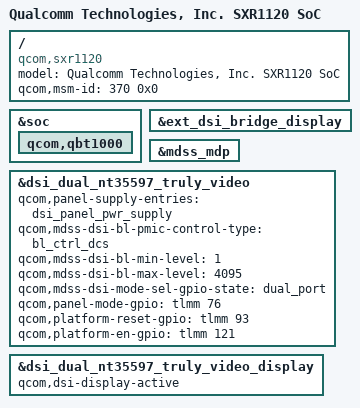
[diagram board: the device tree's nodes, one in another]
/*
 * Copyright (c) 2018, The Linux Foundation. All rights reserved.
 *
 * This program is free software; you can redistribute it and/or modify
 * it under the terms of the GNU General Public License version 2 and
 * only version 2 as published by the Free Software Foundation.
 *
 * This program is distributed in the hope that it will be useful,
 * but WITHOUT ANY WARRANTY; without even the implied warranty of
 * MERCHANTABILITY or FITNESS FOR A PARTICULAR PURPOSE.  See the
 * GNU General Public License for more details.
 */

#include "qcs605-lc.dtsi"

/ {
	model = "Qualcomm Technologies, Inc. SXR1120 SoC";
	compatible = "qcom,sxr1120";
	qcom,msm-id = <370 0x0>;
};

&soc {
	qcom,qbt1000 {
		/delete-property/ qcom,ipc-gpio;
	};
};

&ext_dsi_bridge_display {
	/delete-property/ qcom,dsi-display-active;
};

&mdss_mdp {
	/delete-property/ bridges;
	#cooling-cells = <2>;
};

&dsi_dual_nt35597_truly_video {
	qcom,panel-supply-entries = <&dsi_panel_pwr_supply>;
	qcom,mdss-dsi-bl-pmic-control-type = "bl_ctrl_dcs";
	qcom,mdss-dsi-bl-min-level = <1>;
	qcom,mdss-dsi-bl-max-level = <4095>;
	qcom,mdss-dsi-mode-sel-gpio-state = "dual_port";
	qcom,panel-mode-gpio = <&tlmm 76 0>;
	qcom,platform-reset-gpio = <&tlmm 93 0>;
	qcom,platform-en-gpio = <&tlmm 121 0>;
};

&dsi_dual_nt35597_truly_video_display {
	qcom,dsi-display-active;
};
